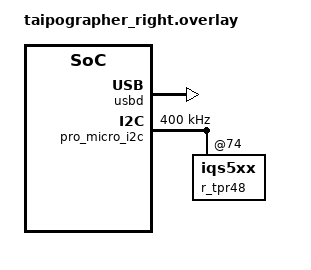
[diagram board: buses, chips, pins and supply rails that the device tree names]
#include "taipographer.dtsi"

&usbd {
  status = "okay";
};

&default_transform {
  row-offset = <3>;
};

&pro_micro_i2c {
  status = "okay";
  clock-frequency = <I2C_BITRATE_FAST>;

  // The local trackpad
  r_tpr48: iqs5xx@74 {
    #include "overlays/tpr48.overlay"
    status = "okay";
  };
};

// Send trackpad events to central
&iqs_split {
  device = <&r_tpr48>;
};

